# S6E2CC register map
File version: 1.1
CPU: 
Registers are 8-bit, read-write, reset 0x0 unless marked. A register's access mark holds for its fields unless they carry their own. Offsets are from the block's base; [hi:lo] are bit positions; {n}, {i} and the like mark numbered series.

## HSSPI — HI-SPEED SPI Controller
Base 0xD0000000
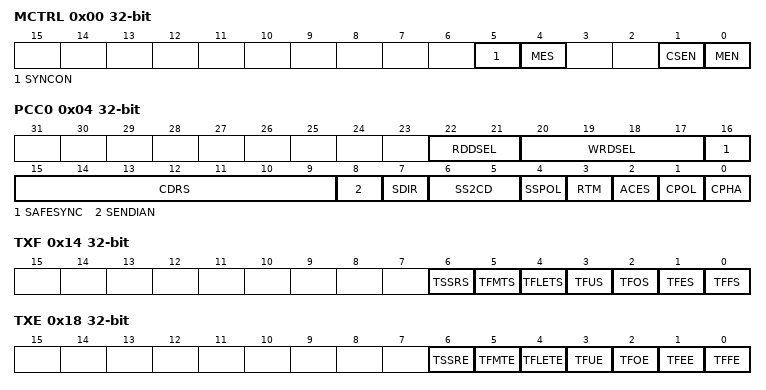
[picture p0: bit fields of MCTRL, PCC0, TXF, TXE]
0x00 MCTRL 32-bit — Control Register
  [5] SYNCON — Synchronizer circuit operation bit
  [4] MES ro — Module enable status bit
  [1] CSEN — Command sequencer mode enable bit
  [0] MEN — Module enable bit
0x04 PCC0 32-bit — Peripheral Communication Setting Register 0
  [22:21] RDDSEL — Read deselect time setting bits
  [20:17] WRDSEL — Write or different command deselect time setting bits
  [16] SAFESYNC — Safe synchronization bit
  [15:9] CDRS — Clock division ratio setting bits
  [8] SENDIAN — Endian setting bit
  [7] SDIR — Shift direction setting bit
  [6:5] SS2CD — Slave-select-to-clock-start delay time setting bit
  [4] SSPOL — Slave select polarity setting bit
  [3] RTM — Timing compensation setting bit
  [2] ACES — Serial data transmission/reception timing setting bit
  [1] CPOL — Serial clock polarity setting bit
  [0] CPHA — Clock phase setting bit
{0x4+4i} PCC{i} 32-bit reset not defined (i=1..3) — Peripheral Communication Setting Registers {i}
0x14 TXF 32-bit ro — Transmission Interrupt Factor Register
  [6] TSSRS — Slave select released detection bit
  [5] TFMTS — TX-FIFO-exceeded-threshold detection bit
  [4] TFLETS — TX-FIFO-less-than-or-equal-to-threshold detection bit
  [3] TFUS — TX-FIFO underrun detection bit
  [2] TFOS — TX-FIFO overrun detection bit
  [1] TFES — TX-FIFO and shift register empty detection bit
  [0] TFFS — TX-FIFO full detection bit
0x18 TXE 32-bit — Transmission Interrupt Enable Register
  [6] TSSRE — Slave select released detection interrupt enable bit
  [5] TFMTE — TX-FIFO-exceeded-threshold detection interrupt enable bit
  [4] TFLETE — TX-FIFO-less-than-or-equal-to-threshold detection interrupt enable bit
  [3] TFUE — TX-FIFO underrun detection interrupt enable bit
  [2] TFOE — TX-FIFO overrun detection interrupt enable bit
  [1] TFEE — TX-FIFO and shift register empty detection interrupt enable bit
  [0] TFFE — TX-FIFO full detection interrupt enable bit
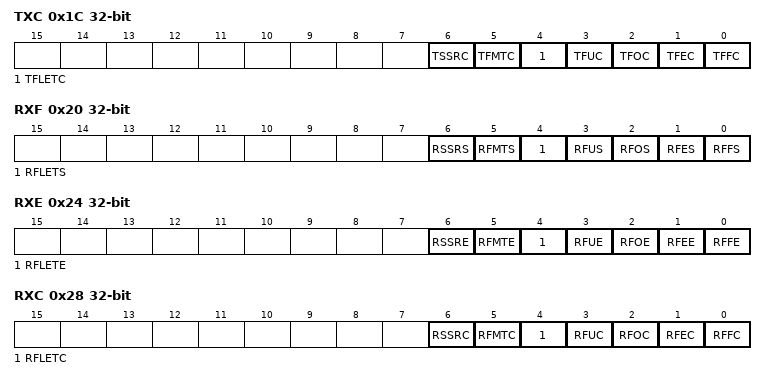
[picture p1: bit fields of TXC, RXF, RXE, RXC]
0x1C TXC 32-bit wo — Transmission Interrupt Clear Register
  [6] TSSRC — Slave select released detection clear bit
  [5] TFMTC — TX-FIFO-exceeded-threshold detection clear bit
  [4] TFLETC — TX-FIFO-less-than-or-equal-to-threshold detection clear bit
  [3] TFUC — TX-FIFO underrun detection clear bit
  [2] TFOC — TX-FIFO overrun detection clear bit
  [1] TFEC — TX-FIFO and shift register empty detection clear bit
  [0] TFFC — TX-FIFO full detection clear bit
0x20 RXF 32-bit ro — Reception Interrupt Factor Register
  [6] RSSRS — Slave select released detection bit
  [5] RFMTS — RX-FIFO-exceeded-threshold detection bit
  [4] RFLETS — RX-FIFO-less-than-or-equal-to-threshold detection bit
  [3] RFUS — RX-FIFO underrun detection bit
  [2] RFOS — RX-FIFO overrun detection bit
  [1] RFES — RX-FIFO empty detection bit
  [0] RFFS — RX-FIFO full detection bit
0x24 RXE 32-bit — Reception Interrupt Enable Register
  [6] RSSRE — Slave select released detection interrupt enable bit
  [5] RFMTE — RX-FIFO-exceeded-threshold detection interrupt enable bit
  [4] RFLETE — RX-FIFO-less-than-or-equal-to-threshold detection interrupt enable bit
  [3] RFUE — RX-FIFO underrun detection interrupt enable bit
  [2] RFOE — RX-FIFO overrun detection interrupt enable bit
  [1] RFEE — RX-FIFO and shift register empty-state detection interrupt enable bit
  [0] RFFE — RX-FIFO full detection interrupt enable bit
0x28 RXC 32-bit wo — Interrupt Clear Register
  [6] RSSRC — Slave select released detection clear bit
  [5] RFMTC — RX-FIFO-exceeded-threshold detection clear bit
  [4] RFLETC — RX-FIFO-less-than-or-equal-to-threshold detection clear bit
  [3] RFUC — RX-FIFO underrun detection clear bit
  [2] RFOC — RX-FIFO overrun detection clear bit
  [1] RFEC — RX-FIFO and shift register empty-state detection clear bit
  [0] RFFC — RX-FIFO full detection clear bit
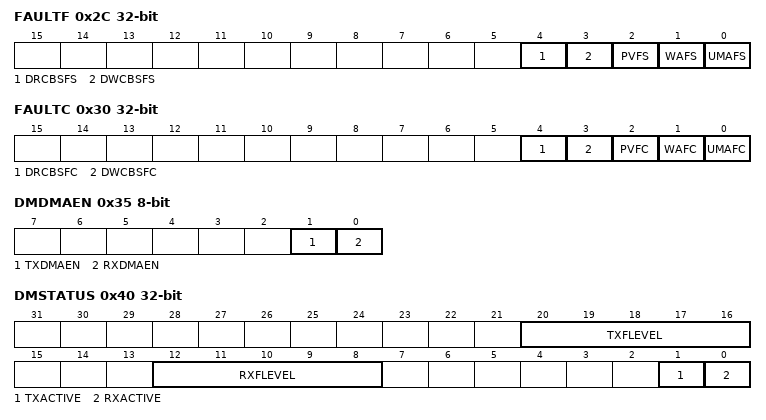
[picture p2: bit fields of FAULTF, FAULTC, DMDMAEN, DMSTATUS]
0x2C FAULTF 32-bit ro — Fault Interrupt Factor Register
  [4] DRCBSFS
  [3] DWCBSFS
  [2] PVFS — Protection violation fault detection bit
  [1] WAFS — Write access fault detection bit
  [0] UMAFS — Unmapped memory access fault detection bit
0x30 FAULTC 32-bit wo — Fault Interrupt Clear Register
  [4] DRCBSFC
  [3] DWCBSFC
  [2] PVFC — Protection violation fault detection clear bit
  [1] WAFC — Write access fault detection clear bit
  [0] UMAFC — Unmapped memory access fault detection clear bit
0x34 DMCFG reset 0x1 — Direct Mode Setting Register
  [1] SSDC — Slave select deassertion setting bit
0x35 DMDMAEN
  [1] TXDMAEN, [0] RXDMAEN
0x38 DMSTART — Direct Mode Transfer Start Control Register
  [0] START — Transfer start bit
0x39 DMSTOP — Direct Mode Transfer Stop Control Register
  [0] STOP — Transfer stop bit
0x3A DMPSEL — Direct Mode Slave Select Register
  [1:0] PSEL — Peripheral select bits
0x3B DMTRP — Direct Mode Transfer Protocol Setting Register
  [3:0] TRP — Transfer protocol setting bits
0x3C DMBCC 16-bit — Direct Mode Transfer Byte Count Setting Register
  [15:0] BCC — Transferred byte count setting value
0x3E DMBCS 16-bit ro — Direct Mode Transfer Remaining Count Register
  [15:0] BCS — Number of remaining bytes to transfer
0x40 DMSTATUS 32-bit ro — Direct Mode Status Register
  [20:16] TXFLEVEL — Remaining TX-FIFO data indication bits
  [12:8] RXFLEVEL — Remaining RX-FIFO data indication bits
  [1] TXACTIVE — Transmission status bit
  [0] RXACTIVE — Reception status bit
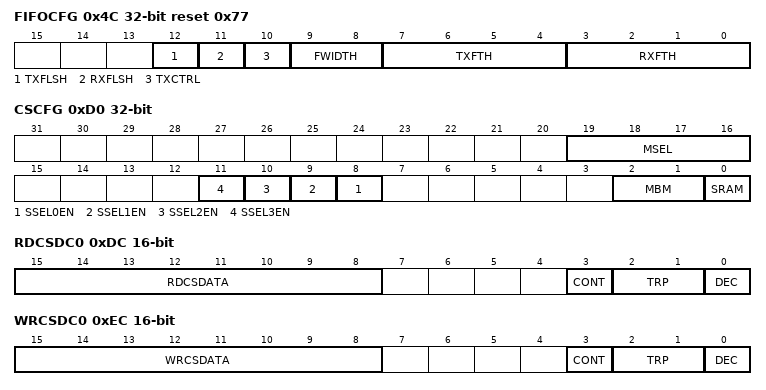
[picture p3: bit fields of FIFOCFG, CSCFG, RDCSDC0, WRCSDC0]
0x4C FIFOCFG 32-bit reset 0x77 — FIFO Setting Register
  [12] TXFLSH wo — TX-FIFO clear bit
  [11] RXFLSH wo — RX-FIFO clear bit
  [10] TXCTRL — TX-FIFO transmission data control bit
  [9:8] FWIDTH — FIFO bit width setting value
  [7:4] TXFTH — TX-FIFO threshold
  [3:0] RXFTH — RX-FIFO threshold
0x50 TXFIFO0 32-bit wo
  [31:0] TXDATA — TX-FIFO0 write data
{0x50+4i} TXFIFO{i} 32-bit reset not defined (i=1..15)
0x90 RXFIFO0 32-bit ro
  [31:0] RXDATA — RX-FIFO0 read data
{0x90+4i} RXFIFO{i} 32-bit reset not defined (i=1..15) — RX-FIFO{i} read data
0xD0 CSCFG 32-bit — 32
  [19:16] MSEL — Memory device selection bits
  [n+8] SSEL{n}EN (n=0..3) — Slave select {n} enable bit
  [2:1] MBM — SPI data width setting bits
  [0] SRAM — Readable/Writable or Read only selection bit
0xD4 CSITIME 32-bit reset 0xFFFF — Command Sequencer Idle Timer Setting Register
  [15:0] ITIME — Idle timer setting value
0xD8 CSAEXT 32-bit — Command Sequencer Address Extension Register
  [31:13] AEXT — Address extension bits
0xDC RDCSDC0 16-bit — Read Command Sequence Data/Control Register 0
  [15:8] RDCSDATA — Read command sequencer data/control setting values
  [3] CONT — Continuous instruction setting bit
  [2:1] TRP — Serial interface width control bits
  [0] DEC — Decode control bit
{0xDC+2i} RDCSDC{i} 32-bit reset not defined (i=1..7) — Read Command Sequence Data/Control Register {i}
0xEC WRCSDC0 16-bit — Write Command Sequence Data/Control Register 0
  [15:8] WRCSDATA — Write command sequencer data/control setting values
  [3] CONT — Continuous instruction setting bit
  [2:1] TRP — Serial interface width control bits
  [0] DEC — Decode control bit
{0xEC+2i} WRCSDC{i} 32-bit reset not defined (i=1..7) — Write Command Sequence Data/Control Register {i}
0xFC MID 32-bit ro reset 0x630 — Module Identification Register
  [31:0] MID — Module identification information bits
0x400 QDCLKR reset 0xF
  [3:0] QHDIV
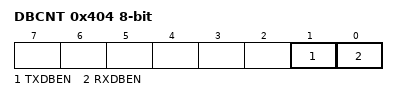
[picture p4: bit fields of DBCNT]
0x404 DBCNT
  [1] TXDBEN, [0] RXDBEN
